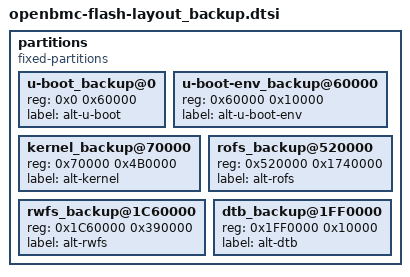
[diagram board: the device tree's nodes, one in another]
// SPDX-License-Identifier: GPL-2.0+

partitions {
	compatible = "fixed-partitions";
	#address-cells = <1>;
	#size-cells = <1>;

	u-boot_backup@0 {
		reg = <0x0 0x60000>;
		label = "alt-u-boot";
	};

	u-boot-env_backup@60000 {
		reg = <0x60000 0x10000>;
		label = "alt-u-boot-env";
	};

	kernel_backup@70000 {
		reg = <0x70000 0x4B0000>;
		label = "alt-kernel";
	};

	rofs_backup@520000 {
		reg = <0x520000 0x1740000>;
		label = "alt-rofs";
	};

	rwfs_backup@1C60000 {
		reg = <0x1C60000 0x390000>;
		label = "alt-rwfs";
	};

	dtb_backup@1FF0000 {
		reg = <0x1FF0000 0x10000>;
		label = "alt-dtb";
	};
};
